# G32R501 register map
Vendor: Geehy Semiconductor Co., Ltd.; Series: G32R5; File version: 1.0
CPU: CM55 r0p1, little endian, MPU, FPU, double-precision FPU, DSP, VTOR, 4 interrupt priority bits
Registers are 32-bit, read-write, reset 0x0 unless marked. A register's access mark holds for its fields unless they carry their own. Offsets are from the block's base; [hi:lo] are bit positions; {n}, {i} and the like mark numbered series.

## XBAR — Crossbar
Base 0x40031000
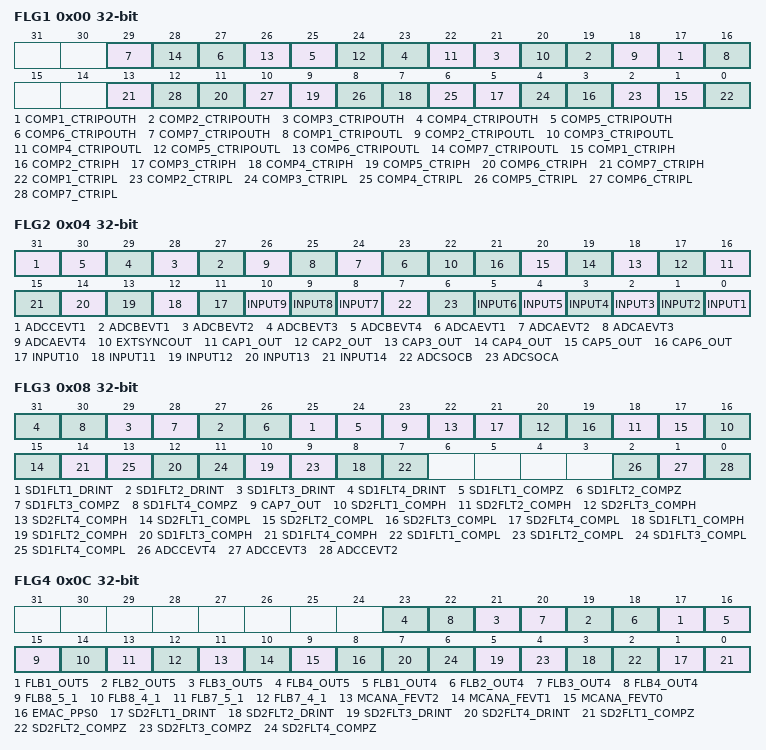
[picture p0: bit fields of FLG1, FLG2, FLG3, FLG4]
0x00 FLG1 ro — X-Bar Input Flag Register 1
  [2n+15] COMP{n}_CTRIPOUTH (n=1..7) — Input Flag for COMP{n}.CTRIPOUTH Signal
  [2n+14] COMP{n}_CTRIPOUTL (n=1..7) — Input Flag for COMP{n}.CTRIPOUTL Signal
  [2n-1] COMP{n}_CTRIPH (n=1..7) — Input Flag for COMP{n}.CTRIPH Signal
  [2n-2] COMP{n}_CTRIPL (n=1..7) — Input Flag for COMP{n}.CTRIPL Signal
0x04 FLG2 ro — X-Bar Input Flag Register 2
  [31] ADCCEVT1 — Input Flag for ADCCEVT1 Signal
  [n+26] ADCBEVT{n} (n=1..4) — Input Flag for ADCBEVT{n} Signal
  [n+22] ADCAEVT{n} (n=1..4) — Input Flag for ADCAEVT{n} Signal
  [22] EXTSYNCOUT — Input Flag for EXTSYNCOUT Signal
  [n+15] CAP{n}_OUT (n=1..6) — Input Flag for CAP{n}.OUT Signal
  [n+1] INPUT{n} (n=7..14) — Input Flag for INPUT{n} Signal
  [7] ADCSOCB — Input Flag for ADCSOCB Signal
  [6] ADCSOCA — Input Flag for ADCSOCA Signal
  [n-1] INPUT{n} (n=1..6) — Input Flag for INPUT{n} Signal
0x08 FLG3 ro — X-Bar Input Flag Register 3
  [2n+23] SD1FLT{n}_DRINT (n=1..4) — Input Flag for SD1FLT{n}.DRINT Signal
  [2n+22] SD1FLT{n}_COMPZ (n=1..4) — Input Flag for SD1FLT{n}.COMPZ Signal
  [23] CAP7_OUT — Input Flag for CAP7.OUT Signal
  [2n+14] SD2FLT{n}_COMPH (n=1..4) — Input Flag for SD2FLT{n}.COMPH Signal
  [2n+13] SD2FLT{n}_COMPL (n=1..4) — Input Flag for SD2FLT{n}.COMPL Signal
  [2n+6] SD1FLT{n}_COMPH (n=1..4) — Input Flag for SD1FLT{n}.COMPH Signal
  [2n+5] SD1FLT{n}_COMPL (n=1..4) — Input Flag for SD1FLT{n}.COMPL Signal
  [2] ADCCEVT4 — Input Flag for ADCCEVT4 Signal
  [1] ADCCEVT3 — Input Flag for ADCCEVT3 Signal
  [0] ADCCEVT2 — Input Flag for ADCCEVT2 Signal
0x0C FLG4 ro — X-Bar Input Flag Register 4
  [2n+15] FLB{n}_OUT5 (n=1..4) — Input Flag for FLB{n}_OUT5 Signal
  [2n+14] FLB{n}_OUT4 (n=1..4) — Input Flag for FLB{n}_OUT4 Signal
  [15] FLB8_5_1 — Input Flag for FLB8_5.1 Signal
  [14] FLB8_4_1 — Input Flag for FLB8_4.1 Signal
  [13] FLB7_5_1 — Input Flag for FLB7_5.1 Signal
  [12] FLB7_4_1 — Input Flag for FLB7_4.1 Signal
  [11] MCANA_FEVT2 — Input Flag for MCANA_FEVT2 Signal
  [10] MCANA_FEVT1 — Input Flag for MCANA_FEVT1 Signal
  [9] MCANA_FEVT0 — Input Flag for MCANA_FEVT0 Signal
  [8] EMAC_PPS0 — Input Flag for EMAC_PPS0 Signal
  [2n-1] SD2FLT{n}_DRINT (n=1..4) — Input Flag for SD2FLT{n}.DRINT Signal
  [2n-2] SD2FLT{n}_COMPZ (n=1..4) — Input Flag for SD2FLT{n}.COMPZ Signal
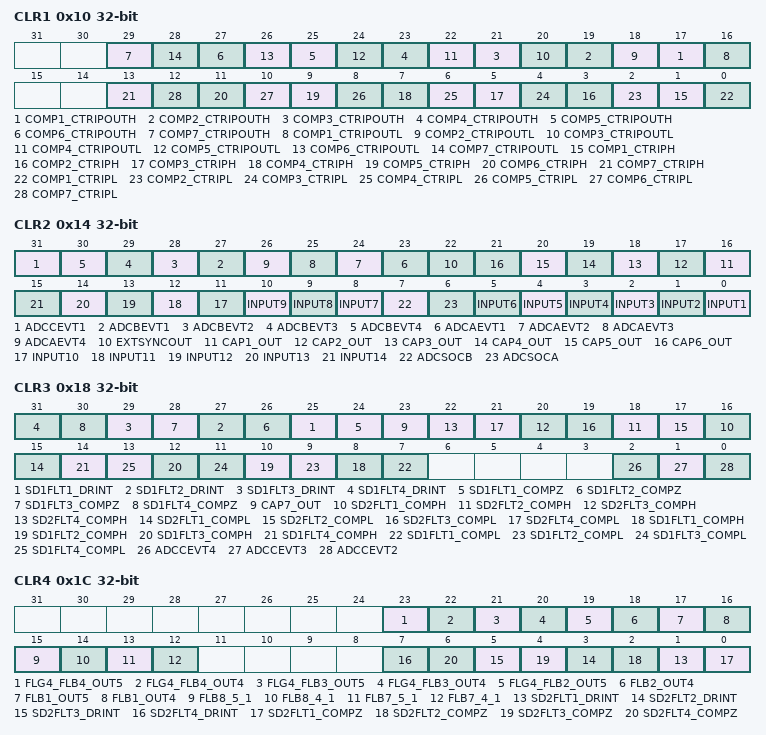
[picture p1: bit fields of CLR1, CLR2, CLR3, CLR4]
0x10 CLR1 — X-Bar Input Flag Clear Register 1
  [2n+15] COMP{n}_CTRIPOUTH (n=1..7) — Input Flag Clear for COMP{n}.CTRIPOUTH Signal
  [2n+14] COMP{n}_CTRIPOUTL (n=1..7) — Input Flag Clear for COMP{n}.CTRIPOUTL Signal
  [2n-1] COMP{n}_CTRIPH (n=1..7) — Input Flag Clear for COMP{n}.CTRIPH Signal
  [2n-2] COMP{n}_CTRIPL (n=1..7) — Input Flag Clear for COMP{n}.CTRIPL Signal
0x14 CLR2 — X-Bar Input Flag Clear Register 2
  [31] ADCCEVT1 — Input Flag Clear for ADCCEVT1 Signal
  [n+26] ADCBEVT{n} (n=1..4) — Input Flag Clear for ADCBEVT{n} Signal
  [n+22] ADCAEVT{n} (n=1..4) — Input Flag Clear for ADCAEVT{n} Signal
  [22] EXTSYNCOUT — Input Flag Clear for EXTSYNCOUT Signal
  [n+15] CAP{n}_OUT (n=1..6) — Input Flag Clear for CAP{n}.OUT Signal
  [n+1] INPUT{n} (n=7..14) — Input Signal for INPUT{n} Signal
  [7] ADCSOCB — Input Flag Clear for ADCSOCB Signal
  [6] ADCSOCA — Input Flag Clear for ADCSOCA Signal
  [n-1] INPUT{n} (n=1..6) — Input Signal for INPUT{n} Signal
0x18 CLR3 — X-Bar Input Flag Clear Register 3
  [2n+23] SD1FLT{n}_DRINT (n=1..4) — Input Flag clear for SD1FLT{n}.DRINT Signal
  [2n+22] SD1FLT{n}_COMPZ (n=1..4) — Input Flag clear for SD1FLT{n}.COMPZ Signal
  [23] CAP7_OUT — Input Flag clear for CAP7.OUT Signal
  [2n+14] SD2FLT{n}_COMPH (n=1..4) — Input Flag Clear for SD2FLT{n}.COMPH Signal
  [2n+13] SD2FLT{n}_COMPL (n=1..4) — Input Flag Clear for SD2FLT{n}.COMPL Signal
  [2n+6] SD1FLT{n}_COMPH (n=1..4) — Input Flag Clear for SD1FLT{n}.COMPH Signal
  [2n+5] SD1FLT{n}_COMPL (n=1..4) — Input Flag Clear for SD1FLT{n}.COMPL Signal
  [2] ADCCEVT4 — Input Flag Clear for ADCCEVT4 Signal
  [1] ADCCEVT3 — Input Flag Clear for ADCCEVT3 Signal
  [0] ADCCEVT2 — Input Flag Clear for ADCCEVT2 Signal
0x1C CLR4 — X-Bar Input Flag Clear Register 4
  [23] FLG4_FLB4_OUT5 — Input Flag clear for FLB4_OUT5 Signal
  [22] FLG4_FLB4_OUT4 — Input Flag clear for FLB4_OUT4 Signal
  [21] FLG4_FLB3_OUT5 — Input Flag clear for FLB3_OUT5 Signal
  [20] FLG4_FLB3_OUT4 — Input Flag clear for FLB3_OUT4 Signal
  [19] FLG4_FLB2_OUT5 — Input Flag clear for FLB2_OUT5 Signal
  [18] FLB2_OUT4 — Input Flag clear for FLB2_OUT4 Signal
  [17] FLB1_OUT5 — Input Flag clear for FLB1_OUT5 Signal
  [16] FLB1_OUT4 — Input Flag clear for FLB1_OUT4 Signal
  [15] FLB8_5_1 — Input Flag clear for FLB8_5_1 Signal
  [14] FLB8_4_1 — Input Flag clear for FLB8_4_1 Signal
  [13] FLB7_5_1 — Input Flag clear for FLB7_5_1 Signal
  [12] FLB7_4_1 — Input Flag clear for FLB7_4_1 Signal
  [2n-1] SD2FLT{n}_DRINT (n=1..4) — Input Flag clear for SD2FLT{n}.DRINT Signal
  [2n-2] SD2FLT{n}_COMPZ (n=1..4) — Input Flag clear for SD2FLT{n}.COMPZ Signal
